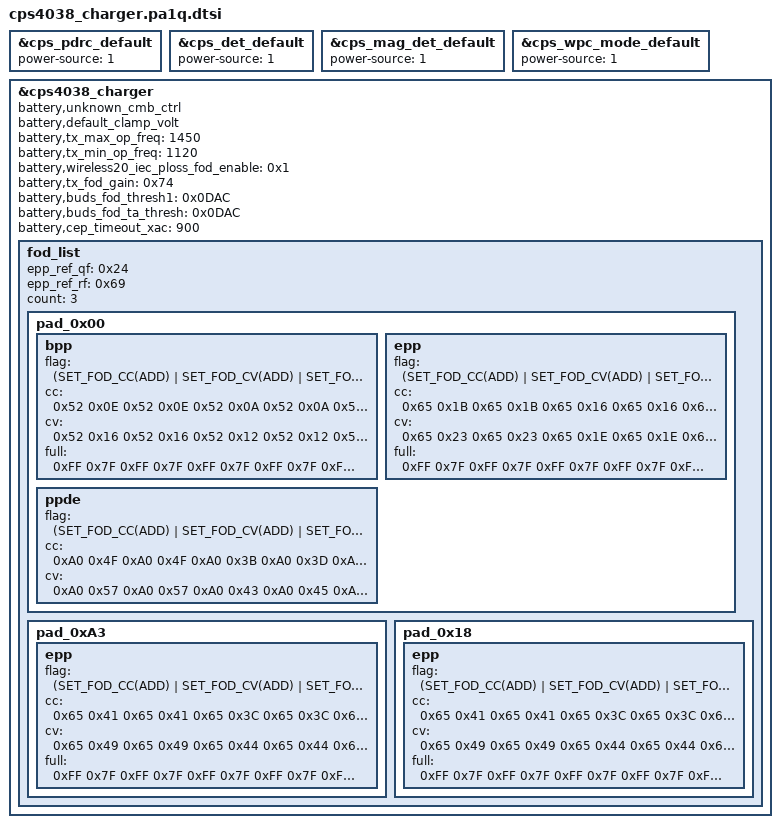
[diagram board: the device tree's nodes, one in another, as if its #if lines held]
#include <dt-bindings/battery/sec-battery.h>

&cps_pdrc_default {
	power-source = <1>; /* need to set default MV gpio to LV */
};

&cps_det_default {
	power-source = <1>; /* need to set default MV gpio to LV */
};

#if ${feature_use_gpio_mag_det}(get)
&cps_mag_det_default {
	power-source = <1>; /* need to set default MV gpio to LV */
};
#endif

#if ${feature_use_gpio_wpc_mode}(get)
&cps_wpc_mode_default {
	power-source = <1>; /* need to set default MV gpio to LV */
};
#endif

&cps4038_charger {
	battery,unknown_cmb_ctrl;
	battery,default_clamp_volt;
	battery,tx_max_op_freq = <1450>;
	battery,tx_min_op_freq = <1120>;
	battery,wireless20_iec_ploss_fod_enable = <0x1>;
	battery,tx_fod_gain = <0x74>;
	battery,buds_fod_thresh1 = <0x0DAC>;
	battery,buds_fod_ta_thresh = <0x0DAC>;
	battery,cep_timeout_xac = <900>;

	fod_list {
		epp_ref_qf = <0x24>;
		epp_ref_rf = <0x69>;

		count = <3>;

		pad_0x00 { /* DEFAULT */
			bpp { /* DEFAULT OP MODE */
				flag = <(SET_FOD_CC(ADD) | SET_FOD_CV(ADD) | SET_FOD_FULL(ADD))>;
				cc = <0x52 0x0E 0x52 0x0E 0x52 0x0A 0x52 0x0A 0x52 0x0A 0x52 0x0A 0x52 0x0B 0x52 0x0B 0x52 0x0B 0x52 0x0B>;
				cv = <0x52 0x16 0x52 0x16 0x52 0x12 0x52 0x12 0x52 0x12 0x52 0x12 0x52 0x13 0x52 0x13 0x52 0x13 0x52 0x13>;
				full = <0xFF 0x7F 0xFF 0x7F 0xFF 0x7F 0xFF 0x7F 0xFF 0x7F 0xFF 0x7F 0xFF 0x7F 0xFF 0x7F 0xFF 0x7F 0xFF 0x7F>;
			};

			epp {
				flag = <(SET_FOD_CC(ADD) | SET_FOD_CV(ADD) | SET_FOD_FULL(ADD))>;
				cc = <0x65 0x1B 0x65 0x1B 0x65 0x16 0x65 0x16 0x65 0x19 0x65 0x19 0x62 0x1D 0x62 0x1D 0x62 0x1D 0x0E 0x03>;
				cv = <0x65 0x23 0x65 0x23 0x65 0x1E 0x65 0x1E 0x65 0x21 0x65 0x21 0x62 0x25 0x62 0x25 0x62 0x25 0x0E 0x03>;
				full = <0xFF 0x7F 0xFF 0x7F 0xFF 0x7F 0xFF 0x7F 0xFF 0x7F 0xFF 0x7F 0xFF 0x7F 0xFF 0x7F 0xFF 0x7F 0x0E 0x03>;
			};

			ppde {
				flag = <(SET_FOD_CC(ADD) | SET_FOD_CV(ADD) | SET_FOD_FULL(USE_DEF_OP))>;
				cc = <0xA0 0x4F 0xA0 0x4F 0xA0 0x3B 0xA0 0x3D 0xA0 0x3E 0xA0 0x3E 0xA0 0x3E 0xA0 0x3B 0xA0 0x39 0xA0 0x39>;
				cv = <0xA0 0x57 0xA0 0x57 0xA0 0x43 0xA0 0x45 0xA0 0x46 0xA0 0x46 0xA0 0x46 0xA0 0x43 0xA0 0x41 0xA0 0x41>;
			};
		};

		pad_0xA3 { /* p2400 */
			epp {
				flag = <(SET_FOD_CC(ADD) | SET_FOD_CV(ADD) | SET_FOD_FULL(ADD))>;
				cc = <0x65 0x41 0x65 0x41 0x65 0x3C 0x65 0x3C 0x65 0x3E 0x65 0x3E 0x62 0x43 0x62 0x43 0x62 0x43 0x0E 0x0A>;
				cv = <0x65 0x49 0x65 0x49 0x65 0x44 0x65 0x44 0x65 0x46 0x65 0x46 0x62 0x4B 0x62 0x4B 0x62 0x4B 0x62 0x4B>;
				full = <0xFF 0x7F 0xFF 0x7F 0xFF 0x7F 0xFF 0x7F 0xFF 0x7F 0xFF 0x7F 0xFF 0x7F 0xFF 0x7F 0xFF 0x7F 0xFF 0x7F>;
			};
		};

		pad_0x18 { /* p2400 */
			epp {
				flag = <(SET_FOD_CC(ADD) | SET_FOD_CV(ADD) | SET_FOD_FULL(ADD))>;
				cc = <0x65 0x41 0x65 0x41 0x65 0x3C 0x65 0x3C 0x65 0x3E 0x65 0x3E 0x62 0x43 0x62 0x43 0x62 0x43 0x0E 0x0A>;
				cv = <0x65 0x49 0x65 0x49 0x65 0x44 0x65 0x44 0x65 0x46 0x65 0x46 0x62 0x4B 0x62 0x4B 0x62 0x4B 0x62 0x4B>;
				full = <0xFF 0x7F 0xFF 0x7F 0xFF 0x7F 0xFF 0x7F 0xFF 0x7F 0xFF 0x7F 0xFF 0x7F 0xFF 0x7F 0xFF 0x7F 0xFF 0x7F>;
			};
		};
	};
};
